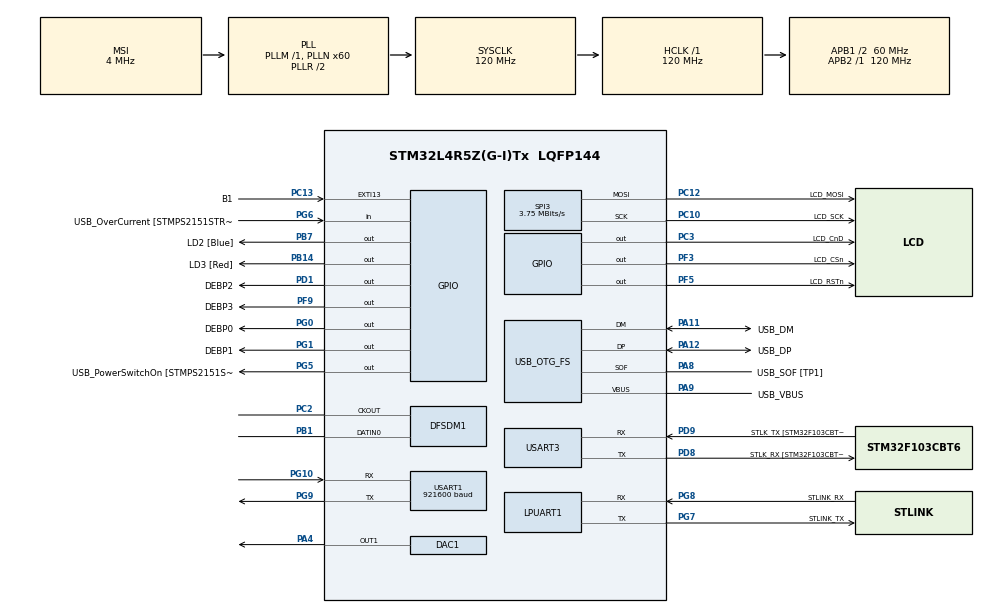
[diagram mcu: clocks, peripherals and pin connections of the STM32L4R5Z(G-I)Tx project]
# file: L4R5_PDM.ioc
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DAC1.DAC_Trigger-DAC_OUT1=DAC_TRIGGER_T2_TRGO
DFSDM1.Divider=117
DFSDM1.DmaMode_reg_FIL0=ENABLE
DFSDM1.DmaMode_reg_FIL1=ENABLE
DFSDM1.FastMode_reg_FIL0=ENABLE
DFSDM1.FastMode_reg_FIL1=ENABLE
DFSDM1.Filter_regChannel_FIL0=DFSDM_CHANNEL_0
DFSDM1.Filter_regChannel_FIL1=DFSDM_CHANNEL_7
DFSDM1.Fosr_FIL0=64
DFSDM1.Fosr_FIL1=64
DFSDM1.SincOrder_FIL0=DFSDM_FILTER_SINC4_ORDER
DFSDM1.SincOrder_FIL1=DFSDM_FILTER_SINC4_ORDER
DFSDM1.Type_spi_CH7=DFSDM_CHANNEL_SPI_FALLING
Dma.DAC1_CH1.4.Direction=DMA_MEMORY_TO_PERIPH
Dma.DAC1_CH1.4.EventEnable=DISABLE
Dma.DAC1_CH1.4.Instance=DMA1_Channel5
Dma.DAC1_CH1.4.MemDataAlignment=DMA_MDATAALIGN_HALFWORD
Dma.DAC1_CH1.4.MemInc=DMA_MINC_ENABLE
Dma.DAC1_CH1.4.Mode=DMA_CIRCULAR
Dma.DAC1_CH1.4.PeriphDataAlignment=DMA_PDATAALIGN_HALFWORD
Dma.DAC1_CH1.4.PeriphInc=DMA_PINC_DISABLE
Dma.DAC1_CH1.4.Polarity=HAL_DMAMUX_REQUEST_GEN_RISING
Dma.DAC1_CH1.4.Priority=DMA_PRIORITY_LOW
Dma.DAC1_CH1.4.RequestNumber=1
Dma.DAC1_CH1.4.SignalID=NONE
Dma.DAC1_CH1.4.SyncEnable=DISABLE
Dma.DAC1_CH1.4.SyncPolarity=HAL_DMAMUX_SYNC_NO_EVENT
Dma.DAC1_CH1.4.SyncRequestNumber=1
Dma.DAC1_CH1.4.SyncSignalID=NONE
Dma.DFSDM1_FLT0.0.Direction=DMA_PERIPH_TO_MEMORY
Dma.DFSDM1_FLT0.0.EventEnable=DISABLE
Dma.DFSDM1_FLT0.0.Instance=DMA1_Channel1
Dma.DFSDM1_FLT0.0.MemDataAlignment=DMA_MDATAALIGN_WORD
Dma.DFSDM1_FLT0.0.MemInc=DMA_MINC_ENABLE
Dma.DFSDM1_FLT0.0.Mode=DMA_CIRCULAR
Dma.DFSDM1_FLT0.0.PeriphDataAlignment=DMA_PDATAALIGN_WORD
Dma.DFSDM1_FLT0.0.PeriphInc=DMA_PINC_DISABLE
Dma.DFSDM1_FLT0.0.Polarity=HAL_DMAMUX_REQUEST_GEN_RISING
Dma.DFSDM1_FLT0.0.Priority=DMA_PRIORITY_LOW
Dma.DFSDM1_FLT0.0.RequestNumber=1
Dma.DFSDM1_FLT0.0.SignalID=NONE
Dma.DFSDM1_FLT0.0.SyncEnable=DISABLE
Dma.DFSDM1_FLT0.0.SyncPolarity=HAL_DMAMUX_SYNC_NO_EVENT
Dma.DFSDM1_FLT0.0.SyncRequestNumber=1
Dma.DFSDM1_FLT0.0.SyncSignalID=NONE
Dma.DFSDM1_FLT1.1.Direction=DMA_PERIPH_TO_MEMORY
Dma.DFSDM1_FLT1.1.EventEnable=DISABLE
Dma.DFSDM1_FLT1.1.Instance=DMA1_Channel2
Dma.DFSDM1_FLT1.1.MemDataAlignment=DMA_MDATAALIGN_WORD
Dma.DFSDM1_FLT1.1.MemInc=DMA_MINC_ENABLE
Dma.DFSDM1_FLT1.1.Mode=DMA_CIRCULAR
Dma.DFSDM1_FLT1.1.PeriphDataAlignment=DMA_PDATAALIGN_WORD
Dma.DFSDM1_FLT1.1.PeriphInc=DMA_PINC_DISABLE
Dma.DFSDM1_FLT1.1.Polarity=HAL_DMAMUX_REQUEST_GEN_RISING
Dma.DFSDM1_FLT1.1.Priority=DMA_PRIORITY_LOW
Dma.DFSDM1_FLT1.1.RequestNumber=1
Dma.DFSDM1_FLT1.1.SignalID=NONE
Dma.DFSDM1_FLT1.1.SyncEnable=DISABLE
Dma.DFSDM1_FLT1.1.SyncPolarity=HAL_DMAMUX_SYNC_NO_EVENT
Dma.DFSDM1_FLT1.1.SyncRequestNumber=1
Dma.DFSDM1_FLT1.1.SyncSignalID=NONE
Dma.Request0=DFSDM1_FLT0
Dma.Request1=DFSDM1_FLT1
Dma.Request2=SPI3_TX
Dma.Request3=USART1_TX
Dma.Request4=DAC1_CH1
Dma.SPI3_TX.2.Direction=DMA_MEMORY_TO_PERIPH
Dma.SPI3_TX.2.EventEnable=DISABLE
Dma.SPI3_TX.2.Instance=DMA1_Channel3
Dma.SPI3_TX.2.MemDataAlignment=DMA_MDATAALIGN_BYTE
Dma.SPI3_TX.2.MemInc=DMA_MINC_ENABLE
Dma.SPI3_TX.2.Mode=DMA_NORMAL
Dma.SPI3_TX.2.PeriphDataAlignment=DMA_PDATAALIGN_BYTE
Dma.SPI3_TX.2.PeriphInc=DMA_PINC_DISABLE
Dma.SPI3_TX.2.Polarity=HAL_DMAMUX_REQUEST_GEN_RISING
Dma.SPI3_TX.2.Priority=DMA_PRIORITY_LOW
Dma.SPI3_TX.2.RequestNumber=1
Dma.SPI3_TX.2.SignalID=NONE
Dma.SPI3_TX.2.SyncEnable=DISABLE
Dma.SPI3_TX.2.SyncPolarity=HAL_DMAMUX_SYNC_NO_EVENT
Dma.SPI3_TX.2.SyncRequestNumber=1
Dma.SPI3_TX.2.SyncSignalID=NONE
Dma.USART1_TX.3.Direction=DMA_MEMORY_TO_PERIPH
Dma.USART1_TX.3.EventEnable=DISABLE
Dma.USART1_TX.3.Instance=DMA1_Channel4
Dma.USART1_TX.3.MemDataAlignment=DMA_MDATAALIGN_BYTE
Dma.USART1_TX.3.MemInc=DMA_MINC_ENABLE
Dma.USART1_TX.3.Mode=DMA_NORMAL
Dma.USART1_TX.3.PeriphDataAlignment=DMA_PDATAALIGN_BYTE
Dma.USART1_TX.3.PeriphInc=DMA_PINC_DISABLE
Dma.USART1_TX.3.Polarity=HAL_DMAMUX_REQUEST_GEN_RISING
Dma.USART1_TX.3.Priority=DMA_PRIORITY_LOW
Dma.USART1_TX.3.RequestNumber=1
Dma.USART1_TX.3.SignalID=NONE
Dma.USART1_TX.3.SyncEnable=DISABLE
Dma.USART1_TX.3.SyncPolarity=HAL_DMAMUX_SYNC_NO_EVENT
Dma.USART1_TX.3.SyncRequestNumber=1
Dma.USART1_TX.3.SyncSignalID=NONE
FREERTOS.Queues01=QueGLCD,32,GRAP_LCD_QUE,0,Dynamic,NULL,NULL;QueSend,4,uint16_t,0,Dynamic,NULL,NULL
FREERTOS.Tasks01=defaultTask,0,128,StartDefaultTask,Default,NULL,Dynamic,NULL,NULL;TASK_MAIN,-3,128,tk_main,As weak,NULL,Dynamic,NULL,NULL;TASK_DISP,-3,128,tk_disp,As weak,NULL,Dynamic,NULL,NULL;TASK_SNS,-3,128,tk_sns,As weak,NULL,Dynamic,NULL,NULL;TASK_COM,-3,128,tk_com,As weak,NULL,Dynamic,NULL,NULL
FREERTOS.configTOTAL_HEAP_SIZE=8192
Mcu.Family=STM32L4
Mcu.Name=STM32L4R5Z(G-I)Tx
Mcu.Package=LQFP144
NVIC.DFSDM1_FLT0_IRQn=true\:5\:0\:false\:false\:true\:true\:true\:true
NVIC.DFSDM1_FLT1_IRQn=true\:5\:0\:false\:false\:true\:true\:true\:true
NVIC.DMA1_Channel1_IRQn=true\:5\:0\:false\:false\:true\:true\:false\:true
NVIC.DMA1_Channel2_IRQn=true\:5\:0\:false\:false\:true\:true\:false\:true
NVIC.DMA1_Channel3_IRQn=true\:5\:0\:false\:false\:true\:true\:false\:true
NVIC.DMA1_Channel4_IRQn=true\:5\:0\:false\:false\:true\:true\:false\:true
NVIC.DMA1_Channel5_IRQn=true\:5\:0\:false\:false\:true\:true\:false\:true
NVIC.PriorityGroup=NVIC_PRIORITYGROUP_4
NVIC.SPI3_IRQn=true\:5\:0\:false\:false\:true\:true\:true\:true
NVIC.TIM1_TRG_COM_TIM17_IRQn=true\:0\:0\:false\:false\:true\:false\:false\:true
NVIC.TIM2_IRQn=true\:5\:0\:false\:false\:true\:true\:true\:true
NVIC.TimeBase=TIM1_TRG_COM_TIM17_IRQn
NVIC.TimeBaseIP=TIM17
NVIC.USART1_IRQn=true\:5\:0\:false\:false\:true\:true\:true\:true
PA10.GPIO_Label=USB_ID
PA10.Signal=USB_OTG_FS_ID
PA11.GPIO_Label=USB_DM
PA11.Mode=Device_Only
PA11.Signal=USB_OTG_FS_DM
PA12.GPIO_Label=USB_DP
PA12.Mode=Device_Only
PA12.Signal=USB_OTG_FS_DP
PA13\ (JTMS/SWDIO).GPIO_Label=TMS
PA13\ (JTMS/SWDIO).Mode=Trace_Asynchronous_SW
PA13\ (JTMS/SWDIO).Signal=SYS_JTMS-SWDIO
PA14\ (JTCK/SWCLK).GPIO_Label=TCK
PA14\ (JTCK/SWCLK).Mode=Trace_Asynchronous_SW
PA14\ (JTCK/SWCLK).Signal=SYS_JTCK-SWCLK
PA4.Signal=COMP_DAC11_group
PA8.GPIO_Label=USB_SOF [TP1]
PA8.Mode=Activate_SOF_FS
PA8.Signal=USB_OTG_FS_SOF
PA9.GPIO_Label=USB_VBUS
PA9.Mode=Activate_VBUS
PA9.Signal=USB_OTG_FS_VBUS
PB1.Signal=S_DATAIN0DFSDM1
PB14.GPIO_Label=LD3 [Red]
PB14.Signal=GPIO_Output
PB3\ (JTDO/TRACESWO).GPIO_Label=SWO
PB3\ (JTDO/TRACESWO).Mode=Trace_Asynchronous_SW
PB3\ (JTDO/TRACESWO).Signal=SYS_JTDO-SWO
PB7.GPIO_Label=LD2 [Blue]
PB7.Signal=GPIO_Output
PC10.GPIO_Label=LCD_SCK
PC10.Mode=TX_Only_Simplex_Unidirect_Master
PC10.Signal=SPI3_SCK
PC12.GPIO_Label=LCD_MOSI
PC12.Mode=TX_Only_Simplex_Unidirect_Master
PC12.Signal=SPI3_MOSI
PC13.GPIO_Label=B1
PC13.Signal=GPXTI13
PC14-OSC32_IN\ (PC14).Mode=LSE-External-Oscillator
PC14-OSC32_IN\ (PC14).Signal=RCC_OSC32_IN
PC15-OSC32_OUT\ (PC15).Mode=LSE-External-Oscillator
PC15-OSC32_OUT\ (PC15).Signal=RCC_OSC32_OUT
PC2.Signal=S_CKOUTDFSDM1
PC3.GPIO_Label=LCD_CnD
PC3.Signal=GPIO_Output
PD1.GPIO_Label=DEBP2
PD1.Signal=GPIO_Output
PD8.GPIO_Label=STLK_RX [STM32F103CBT6_PA3]
PD8.Mode=Asynchronous
PD8.Signal=USART3_TX
PD9.GPIO_Label=STLK_TX [STM32F103CBT6_PA2]
PD9.Mode=Asynchronous
PD9.Signal=USART3_RX
PF3.GPIO_Label=LCD_CSn
PF3.Signal=GPIO_Output
PF5.GPIO_Label=LCD_RSTn
PF5.Signal=GPIO_Output
PF9.GPIO_Label=DEBP3
PF9.Signal=GPIO_Output
PG0.GPIO_Label=DEBP0
PG0.Signal=GPIO_Output
PG1.GPIO_Label=DEBP1
PG1.Signal=GPIO_Output
PG10.Mode=Asynchronous
PG10.Signal=USART1_RX
PG5.GPIO_Label=USB_PowerSwitchOn [STMPS2151STR_EN]
PG5.Signal=GPIO_Output
PG6.GPIO_Label=USB_OverCurrent [STMPS2151STR_FAULT]
PG6.Signal=GPIO_Input
PG7.GPIO_Label=STLINK_TX
PG7.Mode=Asynchronous
PG7.Signal=LPUART1_TX
PG8.GPIO_Label=STLINK_RX
PG8.Mode=Asynchronous
PG8.Signal=LPUART1_RX
PG9.Mode=Asynchronous
PG9.Signal=USART1_TX
PH0-OSC_IN\ (PH0).Mode=HSE-External-Clock-Source
PH0-OSC_IN\ (PH0).Signal=RCC_OSC_IN
PH1-OSC_OUT\ (PH1).Signal=RCC_OSC_OUT
ProjectManager.HeapSize=0x200
ProjectManager.StackSize=0x400
ProjectManager.TargetToolchain=STM32CubeIDE
RCC.48MHZClocksFreq_Value=24000000
RCC.ADCFreq_Value=48000000
RCC.AHBFreq_Value=120000000
RCC.APB1CLKDivider=RCC_HCLK_DIV2
RCC.APB1Freq_Value=60000000
RCC.APB1TimFreq_Value=120000000
RCC.APB2Freq_Value=120000000
RCC.APB2TimFreq_Value=120000000
RCC.CortexFreq_Value=120000000
RCC.DFSDMCLockSelection=RCC_DFSDM1CLKSOURCE_SYSCLK
RCC.HCLKFreq_Value=120000000
RCC.HSE_VALUE=8000000
RCC.HSI48_VALUE=48000000
RCC.HSI_VALUE=16000000
RCC.MSI_VALUE=4000000
RCC.PLLMUL=RCC_PLL_MUL9
RCC.PLLN=60
RCC.PLLSAI1N=24
RCC.PRESCALERUSB=RCC_USBCLKSOURCE_PLL_DIV1_5
RCC.SYSCLKFreq_VALUE=120000000
RCC.SYSCLKSource=RCC_SYSCLKSOURCE_PLLCLK
RCC.SYSCLKSourceVirtual=RCC_SYSCLKSOURCE_PLLCLK
RCC.USBFreq_Value=48000000
RCC.VCOOutputFreq_Value=240000000
SH.COMP_DAC11_group.0=DAC1_OUT1,DAC_OUT1
SH.S_CKOUTDFSDM1.0=DFSDM1_CKOUT,PDM_SPI_Input_from_ch70_and_Internal_Clock
SH.S_CKOUTDFSDM1.1=DFSDM1_CKOUT,CKOUT
SH.S_CKOUTDFSDM1.2=DFSDM1_CKOUT,PDM_SPI_input_from_ch0_and_internal_clock
SH.S_DATAIN0DFSDM1.0=DFSDM1_DATIN0,PDM_SPI_Input_from_ch70_and_Internal_Clock
SH.S_DATAIN0DFSDM1.1=DFSDM1_DATIN0,PDM_SPI_input_from_ch0_and_internal_clock
SPI3.BaudRatePrescaler=SPI_BAUDRATEPRESCALER_16
SPI3.CalculateBaudRate=3.75 MBits/s
SPI3.DataSize=SPI_DATASIZE_8BIT
SPI3.Direction=SPI_DIRECTION_2LINES
SPI3.Mode=SPI_MODE_MASTER
SPI3.VirtualType=VM_MASTER
TIM2.AutoReloadPreload=TIM_AUTORELOAD_PRELOAD_ENABLE
TIM2.Period=7487
TIM2.TIM_MasterOutputTrigger=TIM_TRGO_UPDATE
USART1.BaudRate=921600
USART1.VirtualMode-Asynchronous=VM_ASYNC
USART3.VirtualMode-Asynchronous=VM_ASYNC
USB_OTG_FS.VirtualMode=Device_Only
VP_FREERTOS_VS_CMSIS_V1.Mode=CMSIS_V1
VP_SYS_VS_tim17.Mode=TIM17
VP_TIM2_VS_ClockSourceINT.Mode=Internal
board=NUCLEO-L4R5ZI

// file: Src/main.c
/* USER CODE BEGIN Header */
/**
  ******************************************************************************
  * @file           : main.c
  * @brief          : Main program body
  ******************************************************************************
  * @attention
  *
  * <h2><center>&copy; Copyright (c) 2019 STMicroelectronics.
  * All rights reserved.</center></h2>
  *
  * This software component is licensed by ST under BSD 3-Clause license,
  * the "License"; You may not use this file except in compliance with the
  * License. You may obtain a copy of the License at:
  *                        opensource.org/licenses/BSD-3-Clause
  *
  ******************************************************************************
  */
/* USER CODE END Header */

#include "main.h"
#include "cmsis_os.h"

/* USER CODE BEGIN Includes */
#include "lcd_que.h"
/* USER CODE END Includes */

DAC_HandleTypeDef hdac1;
DMA_HandleTypeDef hdma_dac1_ch1;

DFSDM_Filter_HandleTypeDef hdfsdm1_filter0;
DFSDM_Filter_HandleTypeDef hdfsdm1_filter1;
DFSDM_Channel_HandleTypeDef hdfsdm1_channel0;
DFSDM_Channel_HandleTypeDef hdfsdm1_channel7;
DMA_HandleTypeDef hdma_dfsdm1_flt0;
DMA_HandleTypeDef hdma_dfsdm1_flt1;

UART_HandleTypeDef hlpuart1;
UART_HandleTypeDef huart1;
UART_HandleTypeDef huart3;
DMA_HandleTypeDef hdma_usart1_tx;

SPI_HandleTypeDef hspi3;
DMA_HandleTypeDef hdma_spi3_tx;

TIM_HandleTypeDef htim2;

PCD_HandleTypeDef hpcd_USB_OTG_FS;

osThreadId defaultTaskHandle;
osThreadId TASK_MAINHandle;
osThreadId TASK_DISPHandle;
osThreadId TASK_SNSHandle;
osThreadId TASK_COMHandle;
osMessageQId QueGLCDHandle;
osMessageQId QueSendHandle;

void SystemClock_Config(void);
static void MX_GPIO_Init(void);
static void MX_DMA_Init(void);
static void MX_LPUART1_UART_Init(void);
static void MX_USART3_UART_Init(void);
static void MX_USB_OTG_FS_PCD_Init(void);
static void MX_DFSDM1_Init(void);
static void MX_DAC1_Init(void);
static void MX_USART1_UART_Init(void);
static void MX_SPI3_Init(void);
static void MX_TIM2_Init(void);
void StartDefaultTask(void const * argument);
void tk_main(void const * argument);
void tk_disp(void const * argument);
void tk_sns(void const * argument);
void tk_com(void const * argument);

int main(void)
{

  /* MCU Configuration--------------------------------------------------------*/

  /* Reset of all peripherals, Initializes the Flash interface and the Systick. */
  HAL_Init();

  /* Configure the system clock */
  SystemClock_Config();

  /* Initialize all configured peripherals */
  MX_GPIO_Init();
  MX_DMA_Init();
  MX_LPUART1_UART_Init();
  MX_USART3_UART_Init();
  MX_USB_OTG_FS_PCD_Init();
  MX_DFSDM1_Init();
  MX_DAC1_Init();
  MX_USART1_UART_Init();
  MX_SPI3_Init();
  MX_TIM2_Init();

  /* Create the queue(s) */
  /* definition and creation of QueGLCD */
  osMessageQDef(QueGLCD, 32, GRAP_LCD_QUE);
  QueGLCDHandle = osMessageCreate(osMessageQ(QueGLCD), NULL);

  /* definition and creation of QueSend */
  osMessageQDef(QueSend, 4, uint16_t);
  QueSendHandle = osMessageCreate(osMessageQ(QueSend), NULL);

  /* Create the thread(s) */
  /* definition and creation of defaultTask */
  osThreadDef(defaultTask, StartDefaultTask, osPriorityNormal, 0, 128);
  defaultTaskHandle = osThreadCreate(osThread(defaultTask), NULL);

  /* definition and creation of TASK_MAIN */
  osThreadDef(TASK_MAIN, tk_main, osPriorityIdle, 0, 128);
  TASK_MAINHandle = osThreadCreate(osThread(TASK_MAIN), NULL);

  /* definition and creation of TASK_DISP */
  osThreadDef(TASK_DISP, tk_disp, osPriorityIdle, 0, 128);
  TASK_DISPHandle = osThreadCreate(osThread(TASK_DISP), NULL);

  /* definition and creation of TASK_SNS */
  osThreadDef(TASK_SNS, tk_sns, osPriorityIdle, 0, 128);
  TASK_SNSHandle = osThreadCreate(osThread(TASK_SNS), NULL);

  /* definition and creation of TASK_COM */
  osThreadDef(TASK_COM, tk_com, osPriorityIdle, 0, 128);
  TASK_COMHandle = osThreadCreate(osThread(TASK_COM), NULL);

  /* Start scheduler */
  osKernelStart();

  /* We should never get here as control is now taken by the scheduler */

  /* Infinite loop */
  while (1)
  {

  }
}

void SystemClock_Config(void)
{
  RCC_OscInitTypeDef RCC_OscInitStruct = {0};
  RCC_ClkInitTypeDef RCC_ClkInitStruct = {0};
  RCC_PeriphCLKInitTypeDef PeriphClkInit = {0};

  /** Configure the main internal regulator output voltage
  */
  if (HAL_PWREx_ControlVoltageScaling(PWR_REGULATOR_VOLTAGE_SCALE1_BOOST) != HAL_OK)
  {
    Error_Handler();
  }
  /** Configure LSE Drive Capability
  */
  HAL_PWR_EnableBkUpAccess();
  __HAL_RCC_LSEDRIVE_CONFIG(RCC_LSEDRIVE_LOW);
  /** Initializes the CPU, AHB and APB busses clocks
  */
  RCC_OscInitStruct.OscillatorType = RCC_OSCILLATORTYPE_LSE|RCC_OSCILLATORTYPE_MSI;
  RCC_OscInitStruct.LSEState = RCC_LSE_ON;
  RCC_OscInitStruct.MSIState = RCC_MSI_ON;
  RCC_OscInitStruct.MSICalibrationValue = 0;
  RCC_OscInitStruct.MSIClockRange = RCC_MSIRANGE_6;
  RCC_OscInitStruct.PLL.PLLState = RCC_PLL_ON;
  RCC_OscInitStruct.PLL.PLLSource = RCC_PLLSOURCE_MSI;
  RCC_OscInitStruct.PLL.PLLM = 1;
  RCC_OscInitStruct.PLL.PLLN = 60;
  RCC_OscInitStruct.PLL.PLLP = RCC_PLLP_DIV2;
  RCC_OscInitStruct.PLL.PLLQ = RCC_PLLQ_DIV2;
  RCC_OscInitStruct.PLL.PLLR = RCC_PLLR_DIV2;
  if (HAL_RCC_OscConfig(&RCC_OscInitStruct) != HAL_OK)
  {
    Error_Handler();
  }
  /** Initializes the CPU, AHB and APB busses clocks
  */
  RCC_ClkInitStruct.ClockType = RCC_CLOCKTYPE_HCLK|RCC_CLOCKTYPE_SYSCLK
                              |RCC_CLOCKTYPE_PCLK1|RCC_CLOCKTYPE_PCLK2;
  RCC_ClkInitStruct.SYSCLKSource = RCC_SYSCLKSOURCE_PLLCLK;
  RCC_ClkInitStruct.AHBCLKDivider = RCC_SYSCLK_DIV1;
  RCC_ClkInitStruct.APB1CLKDivider = RCC_HCLK_DIV2;
  RCC_ClkInitStruct.APB2CLKDivider = RCC_HCLK_DIV1;

  if (HAL_RCC_ClockConfig(&RCC_ClkInitStruct, FLASH_LATENCY_5) != HAL_OK)
  {
    Error_Handler();
  }
  PeriphClkInit.PeriphClockSelection = RCC_PERIPHCLK_USART1|RCC_PERIPHCLK_USART3
                              |RCC_PERIPHCLK_LPUART1|RCC_PERIPHCLK_DFSDM1
                              |RCC_PERIPHCLK_USB;
  PeriphClkInit.Usart1ClockSelection = RCC_USART1CLKSOURCE_PCLK2;
  PeriphClkInit.Usart3ClockSelection = RCC_USART3CLKSOURCE_PCLK1;
  PeriphClkInit.Lpuart1ClockSelection = RCC_LPUART1CLKSOURCE_PCLK1;
  PeriphClkInit.Dfsdm1ClockSelection = RCC_DFSDM1CLKSOURCE_SYSCLK;
  PeriphClkInit.UsbClockSelection = RCC_USBCLKSOURCE_PLLSAI1;
  PeriphClkInit.PLLSAI1.PLLSAI1Source = RCC_PLLSOURCE_MSI;
  PeriphClkInit.PLLSAI1.PLLSAI1M = 1;
  PeriphClkInit.PLLSAI1.PLLSAI1N = 24;
  PeriphClkInit.PLLSAI1.PLLSAI1P = RCC_PLLP_DIV2;
  PeriphClkInit.PLLSAI1.PLLSAI1Q = RCC_PLLQ_DIV2;
  PeriphClkInit.PLLSAI1.PLLSAI1R = RCC_PLLR_DIV2;
  PeriphClkInit.PLLSAI1.PLLSAI1ClockOut = RCC_PLLSAI1_48M2CLK;
  if (HAL_RCCEx_PeriphCLKConfig(&PeriphClkInit) != HAL_OK)
  {
    Error_Handler();
  }
  /** Enable MSI Auto calibration
  */
  HAL_RCCEx_EnableMSIPLLMode();
}

static void MX_DAC1_Init(void)
{

  DAC_ChannelConfTypeDef sConfig = {0};

  /** DAC Initialization
  */
  hdac1.Instance = DAC1;
  if (HAL_DAC_Init(&hdac1) != HAL_OK)
  {
    Error_Handler();
  }
  /** DAC channel OUT1 config
  */
  sConfig.DAC_SampleAndHold = DAC_SAMPLEANDHOLD_DISABLE;
  sConfig.DAC_Trigger = DAC_TRIGGER_T2_TRGO;
  sConfig.DAC_HighFrequency = DAC_HIGH_FREQUENCY_INTERFACE_MODE_DISABLE;
  sConfig.DAC_OutputBuffer = DAC_OUTPUTBUFFER_ENABLE;
  sConfig.DAC_ConnectOnChipPeripheral = DAC_CHIPCONNECT_DISABLE;
  sConfig.DAC_UserTrimming = DAC_TRIMMING_FACTORY;
  if (HAL_DAC_ConfigChannel(&hdac1, &sConfig, DAC_CHANNEL_1) != HAL_OK)
  {
    Error_Handler();
  }

}

static void MX_DFSDM1_Init(void)
{

  hdfsdm1_filter0.Instance = DFSDM1_Filter0;
  hdfsdm1_filter0.Init.RegularParam.Trigger = DFSDM_FILTER_SW_TRIGGER;
  hdfsdm1_filter0.Init.RegularParam.FastMode = ENABLE;
  hdfsdm1_filter0.Init.RegularParam.DmaMode = ENABLE;
  hdfsdm1_filter0.Init.FilterParam.SincOrder = DFSDM_FILTER_SINC4_ORDER;
  hdfsdm1_filter0.Init.FilterParam.Oversampling = 64;
  hdfsdm1_filter0.Init.FilterParam.IntOversampling = 1;
  if (HAL_DFSDM_FilterInit(&hdfsdm1_filter0) != HAL_OK)
  {
    Error_Handler();
  }
  hdfsdm1_filter1.Instance = DFSDM1_Filter1;
  hdfsdm1_filter1.Init.RegularParam.Trigger = DFSDM_FILTER_SW_TRIGGER;
  hdfsdm1_filter1.Init.RegularParam.FastMode = ENABLE;
  hdfsdm1_filter1.Init.RegularParam.DmaMode = ENABLE;
  hdfsdm1_filter1.Init.FilterParam.SincOrder = DFSDM_FILTER_SINC4_ORDER;
  hdfsdm1_filter1.Init.FilterParam.Oversampling = 64;
  hdfsdm1_filter1.Init.FilterParam.IntOversampling = 1;
  if (HAL_DFSDM_FilterInit(&hdfsdm1_filter1) != HAL_OK)
  {
    Error_Handler();
  }
  hdfsdm1_channel0.Instance = DFSDM1_Channel0;
  hdfsdm1_channel0.Init.OutputClock.Activation = ENABLE;
  hdfsdm1_channel0.Init.OutputClock.Selection = DFSDM_CHANNEL_OUTPUT_CLOCK_SYSTEM;
  hdfsdm1_channel0.Init.OutputClock.Divider = 117;
  hdfsdm1_channel0.Init.Input.Multiplexer = DFSDM_CHANNEL_EXTERNAL_INPUTS;
  hdfsdm1_channel0.Init.Input.DataPacking = DFSDM_CHANNEL_STANDARD_MODE;
  hdfsdm1_channel0.Init.Input.Pins = DFSDM_CHANNEL_SAME_CHANNEL_PINS;
  hdfsdm1_channel0.Init.SerialInterface.Type = DFSDM_CHANNEL_SPI_RISING;
  hdfsdm1_channel0.Init.SerialInterface.SpiClock = DFSDM_CHANNEL_SPI_CLOCK_INTERNAL;
  hdfsdm1_channel0.Init.Awd.FilterOrder = DFSDM_CHANNEL_FASTSINC_ORDER;
  hdfsdm1_channel0.Init.Awd.Oversampling = 1;
  hdfsdm1_channel0.Init.Offset = 0;
  hdfsdm1_channel0.Init.RightBitShift = 0x00;
  if (HAL_DFSDM_ChannelInit(&hdfsdm1_channel0) != HAL_OK)
  {
    Error_Handler();
  }
  hdfsdm1_channel7.Instance = DFSDM1_Channel7;
  hdfsdm1_channel7.Init.OutputClock.Activation = ENABLE;
  hdfsdm1_channel7.Init.OutputClock.Selection = DFSDM_CHANNEL_OUTPUT_CLOCK_SYSTEM;
  hdfsdm1_channel7.Init.OutputClock.Divider = 117;
  hdfsdm1_channel7.Init.Input.Multiplexer = DFSDM_CHANNEL_EXTERNAL_INPUTS;
  hdfsdm1_channel7.Init.Input.DataPacking = DFSDM_CHANNEL_STANDARD_MODE;
  hdfsdm1_channel7.Init.Input.Pins = DFSDM_CHANNEL_FOLLOWING_CHANNEL_PINS;
  hdfsdm1_channel7.Init.SerialInterface.Type = DFSDM_CHANNEL_SPI_FALLING;
  hdfsdm1_channel7.Init.SerialInterface.SpiClock = DFSDM_CHANNEL_SPI_CLOCK_INTERNAL;
  hdfsdm1_channel7.Init.Awd.FilterOrder = DFSDM_CHANNEL_FASTSINC_ORDER;
  hdfsdm1_channel7.Init.Awd.Oversampling = 1;
  hdfsdm1_channel7.Init.Offset = 0;
  hdfsdm1_channel7.Init.RightBitShift = 0x00;
  if (HAL_DFSDM_ChannelInit(&hdfsdm1_channel7) != HAL_OK)
  {
    Error_Handler();
  }
  if (HAL_DFSDM_FilterConfigRegChannel(&hdfsdm1_filter0, DFSDM_CHANNEL_0, DFSDM_CONTINUOUS_CONV_ON) != HAL_OK)
  {
    Error_Handler();
  }
  if (HAL_DFSDM_FilterConfigRegChannel(&hdfsdm1_filter1, DFSDM_CHANNEL_7, DFSDM_CONTINUOUS_CONV_ON) != HAL_OK)
  {
    Error_Handler();
  }

}

static void MX_LPUART1_UART_Init(void)
{

  hlpuart1.Instance = LPUART1;
  hlpuart1.Init.BaudRate = 209700;
  hlpuart1.Init.WordLength = UART_WORDLENGTH_7B;
  hlpuart1.Init.StopBits = UART_STOPBITS_1;
  hlpuart1.Init.Parity = UART_PARITY_NONE;
  hlpuart1.Init.Mode = UART_MODE_TX_RX;
  hlpuart1.Init.HwFlowCtl = UART_HWCONTROL_NONE;
  hlpuart1.Init.OneBitSampling = UART_ONE_BIT_SAMPLE_DISABLE;
  hlpuart1.Init.ClockPrescaler = UART_PRESCALER_DIV1;
  hlpuart1.AdvancedInit.AdvFeatureInit = UART_ADVFEATURE_NO_INIT;
  hlpuart1.FifoMode = UART_FIFOMODE_DISABLE;
  if (HAL_UART_Init(&hlpuart1) != HAL_OK)
  {
    Error_Handler();
  }
  if (HAL_UARTEx_SetTxFifoThreshold(&hlpuart1, UART_TXFIFO_THRESHOLD_1_8) != HAL_OK)
  {
    Error_Handler();
  }
  if (HAL_UARTEx_SetRxFifoThreshold(&hlpuart1, UART_RXFIFO_THRESHOLD_1_8) != HAL_OK)
  {
    Error_Handler();
  }

}

static void MX_USART1_UART_Init(void)
{

  huart1.Instance = USART1;
  huart1.Init.BaudRate = 921600;
  huart1.Init.WordLength = UART_WORDLENGTH_8B;
  huart1.Init.StopBits = UART_STOPBITS_1;
  huart1.Init.Parity = UART_PARITY_NONE;
  huart1.Init.Mode = UART_MODE_TX_RX;
  huart1.Init.HwFlowCtl = UART_HWCONTROL_NONE;
  huart1.Init.OverSampling = UART_OVERSAMPLING_16;
  huart1.Init.OneBitSampling = UART_ONE_BIT_SAMPLE_DISABLE;
  huart1.Init.ClockPrescaler = UART_PRESCALER_DIV1;
  huart1.AdvancedInit.AdvFeatureInit = UART_ADVFEATURE_NO_INIT;
  if (HAL_UART_Init(&huart1) != HAL_OK)
  {
    Error_Handler();
  }
  if (HAL_UARTEx_SetTxFifoThreshold(&huart1, UART_TXFIFO_THRESHOLD_1_8) != HAL_OK)
  {
    Error_Handler();
  }
  if (HAL_UARTEx_SetRxFifoThreshold(&huart1, UART_RXFIFO_THRESHOLD_1_8) != HAL_OK)
  {
    Error_Handler();
  }
  if (HAL_UARTEx_DisableFifoMode(&huart1) != HAL_OK)
  {
    Error_Handler();
  }

}

static void MX_USART3_UART_Init(void)
{

  huart3.Instance = USART3;
  huart3.Init.BaudRate = 115200;
  huart3.Init.WordLength = UART_WORDLENGTH_8B;
  huart3.Init.StopBits = UART_STOPBITS_1;
  huart3.Init.Parity = UART_PARITY_NONE;
  huart3.Init.Mode = UART_MODE_TX_RX;
  huart3.Init.HwFlowCtl = UART_HWCONTROL_NONE;
  huart3.Init.OverSampling = UART_OVERSAMPLING_16;
  huart3.Init.OneBitSampling = UART_ONE_BIT_SAMPLE_DISABLE;
  huart3.Init.ClockPrescaler = UART_PRESCALER_DIV1;
  huart3.AdvancedInit.AdvFeatureInit = UART_ADVFEATURE_NO_INIT;
  if (HAL_UART_Init(&huart3) != HAL_OK)
  {
    Error_Handler();
  }
  if (HAL_UARTEx_SetTxFifoThreshold(&huart3, UART_TXFIFO_THRESHOLD_1_8) != HAL_OK)
  {
    Error_Handler();
  }
  if (HAL_UARTEx_SetRxFifoThreshold(&huart3, UART_RXFIFO_THRESHOLD_1_8) != HAL_OK)
  {
    Error_Handler();
  }
  if (HAL_UARTEx_DisableFifoMode(&huart3) != HAL_OK)
  {
    Error_Handler();
  }

}

static void MX_SPI3_Init(void)
{

  /* SPI3 parameter configuration*/
  hspi3.Instance = SPI3;
  hspi3.Init.Mode = SPI_MODE_MASTER;
  hspi3.Init.Direction = SPI_DIRECTION_2LINES;
  hspi3.Init.DataSize = SPI_DATASIZE_8BIT;
  hspi3.Init.CLKPolarity = SPI_POLARITY_LOW;
  hspi3.Init.CLKPhase = SPI_PHASE_1EDGE;
  hspi3.Init.NSS = SPI_NSS_SOFT;
  hspi3.Init.BaudRatePrescaler = SPI_BAUDRATEPRESCALER_16;
  hspi3.Init.FirstBit = SPI_FIRSTBIT_MSB;
  hspi3.Init.TIMode = SPI_TIMODE_DISABLE;
  hspi3.Init.CRCCalculation = SPI_CRCCALCULATION_DISABLE;
  hspi3.Init.CRCPolynomial = 7;
  hspi3.Init.CRCLength = SPI_CRC_LENGTH_DATASIZE;
  hspi3.Init.NSSPMode = SPI_NSS_PULSE_ENABLE;
  if (HAL_SPI_Init(&hspi3) != HAL_OK)
  {
    Error_Handler();
  }

}

static void MX_TIM2_Init(void)
{

  TIM_ClockConfigTypeDef sClockSourceConfig = {0};
  TIM_MasterConfigTypeDef sMasterConfig = {0};

  htim2.Instance = TIM2;
  htim2.Init.Prescaler = 0;
  htim2.Init.CounterMode = TIM_COUNTERMODE_UP;
  htim2.Init.Period = 7487;
  htim2.Init.ClockDivision = TIM_CLOCKDIVISION_DIV1;
  htim2.Init.AutoReloadPreload = TIM_AUTORELOAD_PRELOAD_ENABLE;
  if (HAL_TIM_Base_Init(&htim2) != HAL_OK)
  {
    Error_Handler();
  }
  sClockSourceConfig.ClockSource = TIM_CLOCKSOURCE_INTERNAL;
  if (HAL_TIM_ConfigClockSource(&htim2, &sClockSourceConfig) != HAL_OK)
  {
    Error_Handler();
  }
  sMasterConfig.MasterOutputTrigger = TIM_TRGO_UPDATE;
  sMasterConfig.MasterSlaveMode = TIM_MASTERSLAVEMODE_DISABLE;
  if (HAL_TIMEx_MasterConfigSynchronization(&htim2, &sMasterConfig) != HAL_OK)
  {
    Error_Handler();
  }

}

static void MX_USB_OTG_FS_PCD_Init(void)
{

  hpcd_USB_OTG_FS.Instance = USB_OTG_FS;
  hpcd_USB_OTG_FS.Init.dev_endpoints = 6;
  hpcd_USB_OTG_FS.Init.phy_itface = PCD_PHY_EMBEDDED;
  hpcd_USB_OTG_FS.Init.Sof_enable = ENABLE;
  hpcd_USB_OTG_FS.Init.low_power_enable = DISABLE;
  hpcd_USB_OTG_FS.Init.lpm_enable = DISABLE;
  hpcd_USB_OTG_FS.Init.battery_charging_enable = ENABLE;
  hpcd_USB_OTG_FS.Init.use_dedicated_ep1 = DISABLE;
  hpcd_USB_OTG_FS.Init.vbus_sensing_enable = ENABLE;
  if (HAL_PCD_Init(&hpcd_USB_OTG_FS) != HAL_OK)
  {
    Error_Handler();
  }

}

static void MX_DMA_Init(void)
{
  /* DMA controller clock enable */
  __HAL_RCC_DMAMUX1_CLK_ENABLE();
  __HAL_RCC_DMA1_CLK_ENABLE();

  /* DMA interrupt init */
  /* DMA1_Channel1_IRQn interrupt configuration */
  HAL_NVIC_SetPriority(DMA1_Channel1_IRQn, 5, 0);
  HAL_NVIC_EnableIRQ(DMA1_Channel1_IRQn);
  /* DMA1_Channel2_IRQn interrupt configuration */
  HAL_NVIC_SetPriority(DMA1_Channel2_IRQn, 5, 0);
  HAL_NVIC_EnableIRQ(DMA1_Channel2_IRQn);
  /* DMA1_Channel3_IRQn interrupt configuration */
  HAL_NVIC_SetPriority(DMA1_Channel3_IRQn, 5, 0);
  HAL_NVIC_EnableIRQ(DMA1_Channel3_IRQn);
  /* DMA1_Channel4_IRQn interrupt configuration */
  HAL_NVIC_SetPriority(DMA1_Channel4_IRQn, 5, 0);
  HAL_NVIC_EnableIRQ(DMA1_Channel4_IRQn);
  /* DMA1_Channel5_IRQn interrupt configuration */
  HAL_NVIC_SetPriority(DMA1_Channel5_IRQn, 5, 0);
  HAL_NVIC_EnableIRQ(DMA1_Channel5_IRQn);

}

static void MX_GPIO_Init(void)
{
  GPIO_InitTypeDef GPIO_InitStruct = {0};

  /* GPIO Ports Clock Enable */
  __HAL_RCC_GPIOC_CLK_ENABLE();
  __HAL_RCC_GPIOF_CLK_ENABLE();
  __HAL_RCC_GPIOH_CLK_ENABLE();
  __HAL_RCC_GPIOA_CLK_ENABLE();
  __HAL_RCC_GPIOB_CLK_ENABLE();
  __HAL_RCC_GPIOG_CLK_ENABLE();
  __HAL_RCC_GPIOD_CLK_ENABLE();
  HAL_PWREx_EnableVddIO2();

  /*Configure GPIO pin Output Level */
  HAL_GPIO_WritePin(GPIOF, LCD_CSn_Pin|LCD_RSTn_Pin|DEBP3_Pin, GPIO_PIN_RESET);

  /*Configure GPIO pin Output Level */
  HAL_GPIO_WritePin(LCD_CnD_GPIO_Port, LCD_CnD_Pin, GPIO_PIN_RESET);

  /*Configure GPIO pin Output Level */
  HAL_GPIO_WritePin(GPIOG, DEBP0_Pin|DEBP1_Pin|USB_PowerSwitchOn_Pin, GPIO_PIN_RESET);

  /*Configure GPIO pin Output Level */
  HAL_GPIO_WritePin(GPIOB, LD3_Pin|LD2_Pin, GPIO_PIN_RESET);

  /*Configure GPIO pin Output Level */
  HAL_GPIO_WritePin(DEBP2_GPIO_Port, DEBP2_Pin, GPIO_PIN_RESET);

  /*Configure GPIO pin : B1_Pin */
  GPIO_InitStruct.Pin = B1_Pin;
  GPIO_InitStruct.Mode = GPIO_MODE_IT_RISING;
  GPIO_InitStruct.Pull = GPIO_NOPULL;
  HAL_GPIO_Init(B1_GPIO_Port, &GPIO_InitStruct);

  /*Configure GPIO pins : LCD_CSn_Pin LCD_RSTn_Pin DEBP3_Pin */
  GPIO_InitStruct.Pin = LCD_CSn_Pin|LCD_RSTn_Pin|DEBP3_Pin;
  GPIO_InitStruct.Mode = GPIO_MODE_OUTPUT_PP;
  GPIO_InitStruct.Pull = GPIO_NOPULL;
  GPIO_InitStruct.Speed = GPIO_SPEED_FREQ_LOW;
  HAL_GPIO_Init(GPIOF, &GPIO_InitStruct);

  /*Configure GPIO pin : LCD_CnD_Pin */
  GPIO_InitStruct.Pin = LCD_CnD_Pin;
  GPIO_InitStruct.Mode = GPIO_MODE_OUTPUT_PP;
  GPIO_InitStruct.Pull = GPIO_NOPULL;
  GPIO_InitStruct.Speed = GPIO_SPEED_FREQ_LOW;
  HAL_GPIO_Init(LCD_CnD_GPIO_Port, &GPIO_InitStruct);

  /*Configure GPIO pins : DEBP0_Pin DEBP1_Pin USB_PowerSwitchOn_Pin */
  GPIO_InitStruct.Pin = DEBP0_Pin|DEBP1_Pin|USB_PowerSwitchOn_Pin;
  GPIO_InitStruct.Mode = GPIO_MODE_OUTPUT_PP;
  GPIO_InitStruct.Pull = GPIO_NOPULL;
  GPIO_InitStruct.Speed = GPIO_SPEED_FREQ_LOW;
  HAL_GPIO_Init(GPIOG, &GPIO_InitStruct);

  /*Configure GPIO pins : LD3_Pin LD2_Pin */
  GPIO_InitStruct.Pin = LD3_Pin|LD2_Pin;
  GPIO_InitStruct.Mode = GPIO_MODE_OUTPUT_PP;
  GPIO_InitStruct.Pull = GPIO_NOPULL;
  GPIO_InitStruct.Speed = GPIO_SPEED_FREQ_LOW;
  HAL_GPIO_Init(GPIOB, &GPIO_InitStruct);

  /*Configure GPIO pin : USB_OverCurrent_Pin */
  GPIO_InitStruct.Pin = USB_OverCurrent_Pin;
  GPIO_InitStruct.Mode = GPIO_MODE_INPUT;
  GPIO_InitStruct.Pull = GPIO_NOPULL;
  HAL_GPIO_Init(USB_OverCurrent_GPIO_Port, &GPIO_InitStruct);

  /*Configure GPIO pin : DEBP2_Pin */
  GPIO_InitStruct.Pin = DEBP2_Pin;
  GPIO_InitStruct.Mode = GPIO_MODE_OUTPUT_PP;
  GPIO_InitStruct.Pull = GPIO_NOPULL;
  GPIO_InitStruct.Speed = GPIO_SPEED_FREQ_LOW;
  HAL_GPIO_Init(DEBP2_GPIO_Port, &GPIO_InitStruct);

}

void StartDefaultTask(void const * argument)
{

  for(;;)
  {
    osDelay(1);
  }
}

__weak void tk_main(void const * argument)
{
  for(;;)
  {
    osDelay(1);
  }
}

__weak void tk_disp(void const * argument)
{
  for(;;)
  {
    osDelay(1);
  }
}

__weak void tk_sns(void const * argument)
{
  for(;;)
  {
    osDelay(1);
  }
}

__weak void tk_com(void const * argument)
{
  for(;;)
  {
    osDelay(1);
  }
}

void HAL_TIM_PeriodElapsedCallback(TIM_HandleTypeDef *htim)
{
  if (htim->Instance == TIM17) {
    HAL_IncTick();
  }
}

void Error_Handler(void)
{
}

/************************ (C) COPYRIGHT STMicroelectronics *****END OF FILE****/
